# HT32F125x register map
File version: 1.1
CPU: CM3 r2p0, little endian, no MPU, no FPU, 4 interrupt priority bits
Registers are 32-bit, read-write, reset 0x0 unless marked. A register's access mark holds for its fields unless they carry their own. Offsets are from the block's base; [hi:lo] are bit positions; {n}, {i} and the like mark numbered series.

## OPACMP
Base 0x40018000
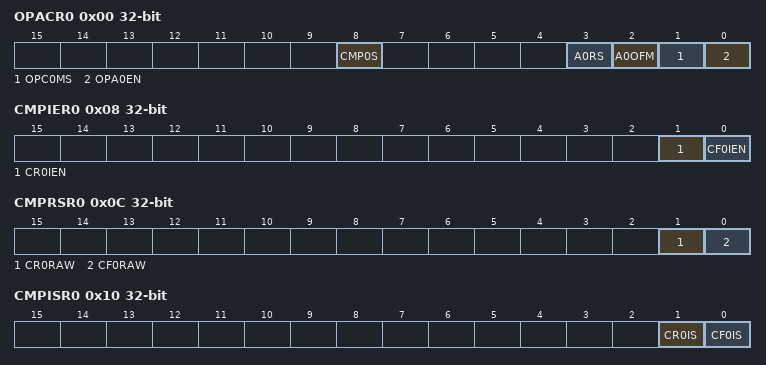
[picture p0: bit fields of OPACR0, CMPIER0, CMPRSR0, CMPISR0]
0x00 OPACR0
  [8] CMP0S, [3] A0RS, [2] A0OFM, [1] OPC0MS, [0] OPA0EN
0x04 OFVCR0
  [5:0] A0OF
0x08 CMPIER0
  [1] CR0IEN, [0] CF0IEN
0x0C CMPRSR0
  [1] CR0RAW, [0] CF0RAW
0x10 CMPISR0
  [1] CR0IS, [0] CF0IS
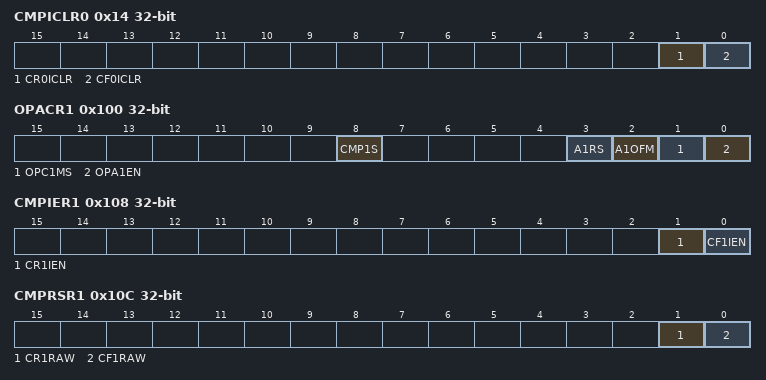
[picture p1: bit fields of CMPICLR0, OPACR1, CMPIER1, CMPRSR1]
0x14 CMPICLR0
  [1] CR0ICLR, [0] CF0ICLR
0x100 OPACR1
  [8] CMP1S, [3] A1RS, [2] A1OFM, [1] OPC1MS, [0] OPA1EN
0x104 OFVCR1
  [5:0] A1OF
0x108 CMPIER1
  [1] CR1IEN, [0] CF1IEN
0x10C CMPRSR1
  [1] CR1RAW, [0] CF1RAW
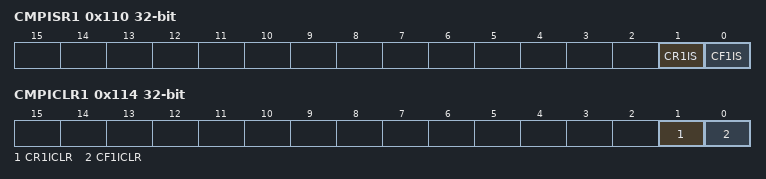
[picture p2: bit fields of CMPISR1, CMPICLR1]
0x110 CMPISR1
  [1] CR1IS, [0] CF1IS
0x114 CMPICLR1
  [1] CR1ICLR, [0] CF1ICLR

## GPTM0
Base 0x4006E000
Same registers: GPTM1 0x4006F000
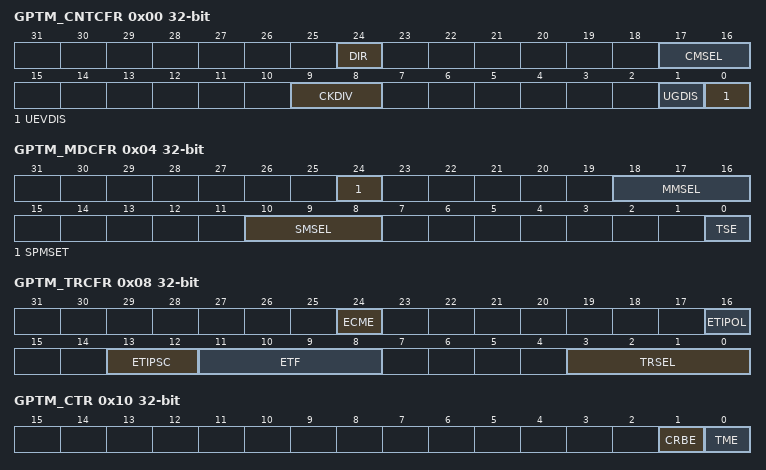
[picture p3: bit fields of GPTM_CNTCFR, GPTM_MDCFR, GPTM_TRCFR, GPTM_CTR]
0x00 GPTM_CNTCFR
  [24] DIR, [17:16] CMSEL, [9:8] CKDIV, [1] UGDIS, [0] UEVDIS
0x04 GPTM_MDCFR
  [24] SPMSET, [18:16] MMSEL, [10:8] SMSEL, [0] TSE
0x08 GPTM_TRCFR
  [24] ECME, [16] ETIPOL, [13:12] ETIPSC, [11:8] ETF, [3:0] TRSEL
0x10 GPTM_CTR
  [1] CRBE, [0] TME
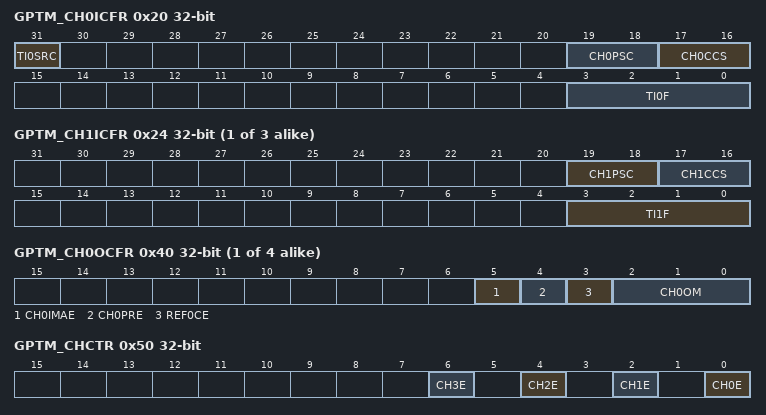
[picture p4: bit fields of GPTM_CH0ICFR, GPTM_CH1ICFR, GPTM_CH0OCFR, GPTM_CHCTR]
0x20 GPTM_CH0ICFR
  [31] TI0SRC, [19:18] CH0PSC, [17:16] CH0CCS, [3:0] TI0F
{0x20+4i} GPTM_CH{i}ICFR (i=1..3)
  [19:18] CH{i}PSC, [17:16] CH{i}CCS, [3:0] TI{i}F
{0x40+4i} GPTM_CH{i}OCFR (i=0..3)
  [5] CH{i}IMAE, [4] CH{i}PRE, [3] REF{i}CE, [2:0] CH{i}OM
0x50 GPTM_CHCTR
  [2n] CH{n}E (n=0..3)
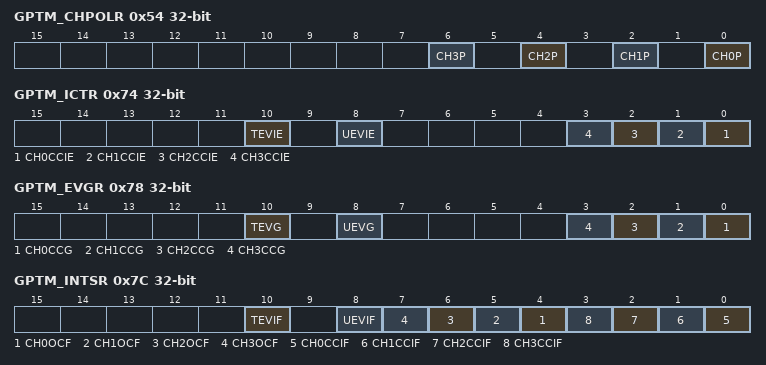
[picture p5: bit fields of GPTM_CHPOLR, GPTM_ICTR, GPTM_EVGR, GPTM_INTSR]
0x54 GPTM_CHPOLR
  [2n] CH{n}P (n=0..3)
0x74 GPTM_ICTR
  [10] TEVIE, [8] UEVIE, [n] CH{n}CCIE (n=0..3)
0x78 GPTM_EVGR
  [10] TEVG, [8] UEVG, [n] CH{n}CCG (n=0..3)
0x7C GPTM_INTSR
  [10] TEVIF, [8] UEVIF, [n+4] CH{n}OCF (n=0..3), [n] CH{n}CCIF (n=0..3)
0x80 GPTM_CNTR
  [15:0] CNTV
0x84 GPTM_PSCR
  [15:0] PSCV
0x88 GPTM_CRR
  [15:0] CRV
{0x90+4i} GPTM_CH{i}CCR (i=0..3)
  [15:0] CH{i}CCV

## RTC
Base 0x4006A000
0x00 RTC_CNT
  [31:0] RTCCNT
0x04 RTC_CMP
  [31:0] RTCCMP
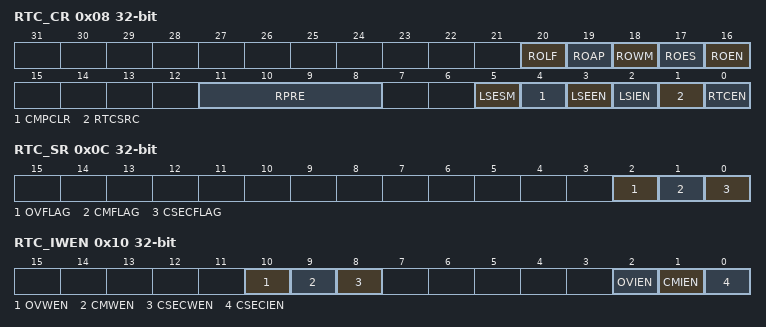
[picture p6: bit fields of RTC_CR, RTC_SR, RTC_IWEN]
0x08 RTC_CR
  [20] ROLF, [19] ROAP, [18] ROWM, [17] ROES, [16] ROEN, [11:8] RPRE, [5] LSESM, [4] CMPCLR, [3] LSEEN, [2] LSIEN, [1] RTCSRC, [0] RTCEN
0x0C RTC_SR
  [2] OVFLAG, [1] CMFLAG, [0] CSECFLAG
0x10 RTC_IWEN
  [10] OVWEN, [9] CMWEN, [8] CSECWEN, [2] OVIEN, [1] CMIEN, [0] CSECIEN

## WDT
Base 0x40068000
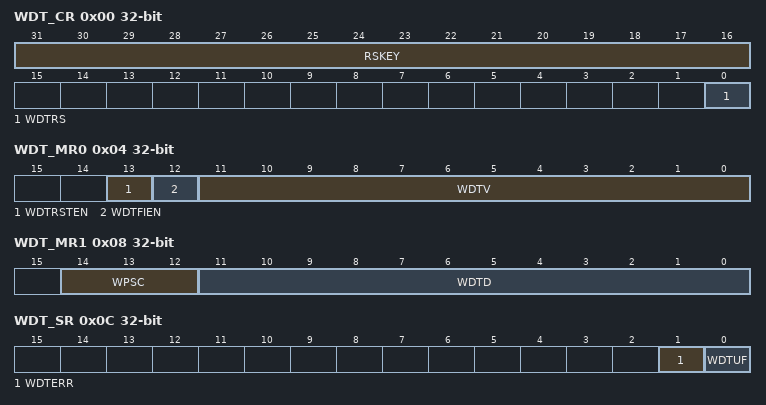
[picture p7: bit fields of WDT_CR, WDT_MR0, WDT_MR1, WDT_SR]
0x00 WDT_CR
  [31:16] RSKEY, [0] WDTRS
0x04 WDT_MR0
  [13] WDTRSTEN, [12] WDTFIEN, [11:0] WDTV
0x08 WDT_MR1
  [14:12] WPSC, [11:0] WDTD
0x0C WDT_SR
  [1] WDTERR, [0] WDTUF
0x10 WDT_PR
  [15:0] PROTECT

## I2C
Base 0x40048000
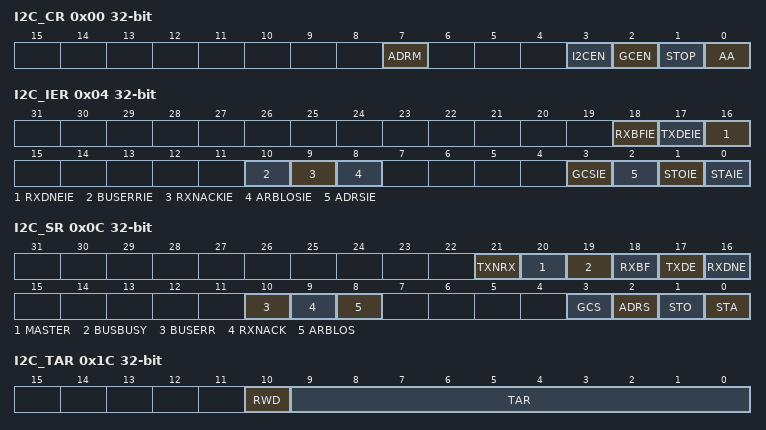
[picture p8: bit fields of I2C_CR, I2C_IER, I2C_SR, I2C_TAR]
0x00 I2C_CR
  [7] ADRM, [3] I2CEN, [2] GCEN, [1] STOP, [0] AA
0x04 I2C_IER
  [18] RXBFIE, [17] TXDEIE, [16] RXDNEIE, [10] BUSERRIE, [9] RXNACKIE, [8] ARBLOSIE, [3] GCSIE, [2] ADRSIE, [1] STOIE, [0] STAIE
0x08 I2C_ADDR
  [9:0] ADDR
0x0C I2C_SR
  [21] TXNRX, [20] MASTER, [19] BUSBUSY, [18] RXBF, [17] TXDE, [16] RXDNE, [10] BUSERR, [9] RXNACK, [8] ARBLOS, [3] GCS, [2] ADRS, [1] STO, [0] STA
0x10 I2C_SHPGR
  [15:0] SHPG
0x14 I2C_SLPGR
  [15:0] SLPG
0x18 I2C_DR
  [7:0] DATA
0x1C I2C_TAR
  [10] RWD, [9:0] TAR

## SPI
Base 0x40004000
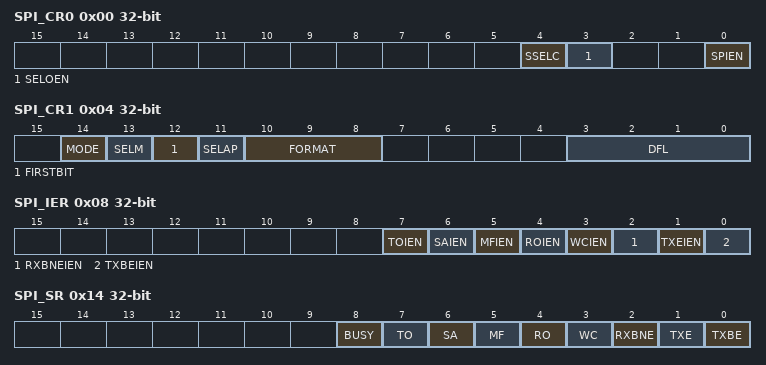
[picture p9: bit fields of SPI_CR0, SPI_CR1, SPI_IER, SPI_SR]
0x00 SPI_CR0
  [4] SSELC, [3] SELOEN, [0] SPIEN
0x04 SPI_CR1
  [14] MODE, [13] SELM, [12] FIRSTBIT, [11] SELAP, [10:8] FORMAT, [3:0] DFL
0x08 SPI_IER
  [7] TOIEN, [6] SAIEN, [5] MFIEN, [4] ROIEN, [3] WCIEN, [2] RXBNEIEN, [1] TXEIEN, [0] TXBEIEN
0x0C SPI_CPR
  [15:0] CP
0x10 SPI_DR
  [15:0] DR
0x14 SPI_SR
  [8] BUSY, [7] TO, [6] SA, [5] MF, [4] RO, [3] WC, [2] RXBNE, [1] TXE, [0] TXBE
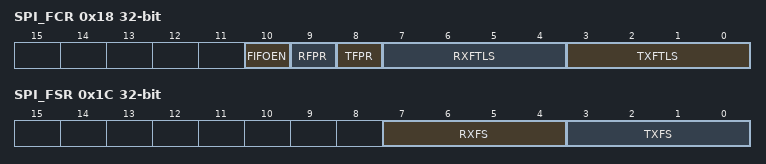
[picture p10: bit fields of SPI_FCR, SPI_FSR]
0x18 SPI_FCR
  [10] FIFOEN, [9] RFPR, [8] TFPR, [7:4] RXFTLS, [3:0] TXFTLS
0x1C SPI_FSR
  [7:4] RXFS, [3:0] TXFS
0x20 SPI_FTOCR
  [31:0] TOC

## USART
Base 0x40000000
0x00 USART_RBR
  [8:0] RD
0x00 USART_TBR (USART view)
  [8:0] TD
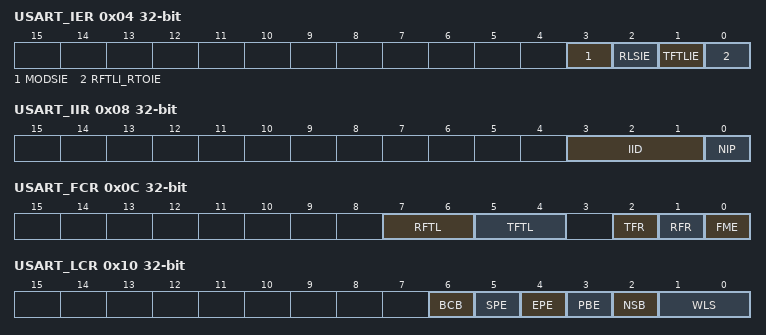
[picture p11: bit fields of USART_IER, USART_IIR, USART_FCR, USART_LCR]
0x04 USART_IER
  [3] MODSIE, [2] RLSIE, [1] TFTLIE, [0] RFTLI_RTOIE
0x08 USART_IIR
  [3:1] IID, [0] NIP
0x0C USART_FCR
  [7:6] RFTL, [5:4] TFTL, [2] TFR, [1] RFR, [0] FME
0x10 USART_LCR
  [6] BCB, [5] SPE, [4] EPE, [3] PBE, [2] NSB, [1:0] WLS
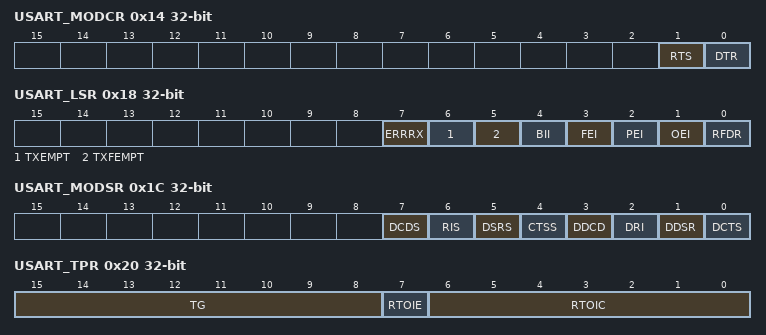
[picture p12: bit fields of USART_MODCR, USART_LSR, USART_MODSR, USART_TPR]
0x14 USART_MODCR
  [1] RTS, [0] DTR
0x18 USART_LSR
  [7] ERRRX, [6] TXEMPT, [5] TXFEMPT, [4] BII, [3] FEI, [2] PEI, [1] OEI, [0] RFDR
0x1C USART_MODSR
  [7] DCDS, [6] RIS, [5] DSRS, [4] CTSS, [3] DDCD, [2] DRI, [1] DDSR, [0] DCTS
0x20 USART_TPR
  [15:8] TG, [7] RTOIE, [6:0] RTOIC
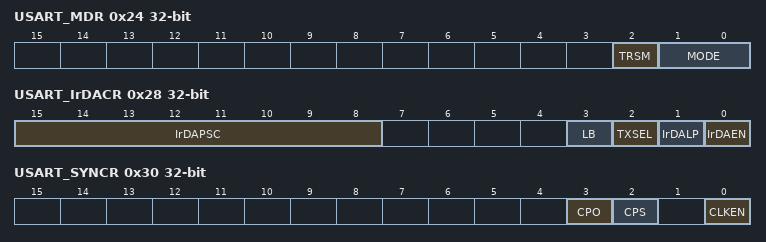
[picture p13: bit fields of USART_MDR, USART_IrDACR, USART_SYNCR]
0x24 USART_MDR
  [2] TRSM, [1:0] MODE
0x28 USART_IrDACR
  [15:8] IrDAPSC, [3] LB, [2] TXSEL, [1] IrDALP, [0] IrDAEN
0x2C USART_RS485CR
  [0] TXENP
0x30 USART_SYNCR
  [3] CPO, [2] CPS, [0] CLKEN
0x34 USART_DEGTSTR
  [1:0] LBM
0x38 USART_DLR
  [15:0] BRD

## Notices in the file
Copyright (C) 2010 ARM Limited. All rights reserved.
ARM Limited (ARM) is supplying this SVD description for use with Cortex-M3
processor based microcontrollers.  This file and or content can be freely
distributed within development tools that are supporting such ARM based
processors.
THIS SOFTWARE IS PROVIDED "AS IS".  NO WARRANTIES, WHETHER EXPRESS, IMPLIED
OR STATUTORY, INCLUDING, BUT NOT LIMITED TO, IMPLIED WARRANTIES OF
MERCHANTABILITY AND FITNESS FOR A PARTICULAR PURPOSE APPLY TO THIS SOFTWARE.
ARM SHALL NOT, IN ANY CIRCUMSTANCES, BE LIABLE FOR SPECIAL, INCIDENTAL, OR
CONSEQUENTIAL DAMAGES, FOR ANY REASON WHATSOEVER.
